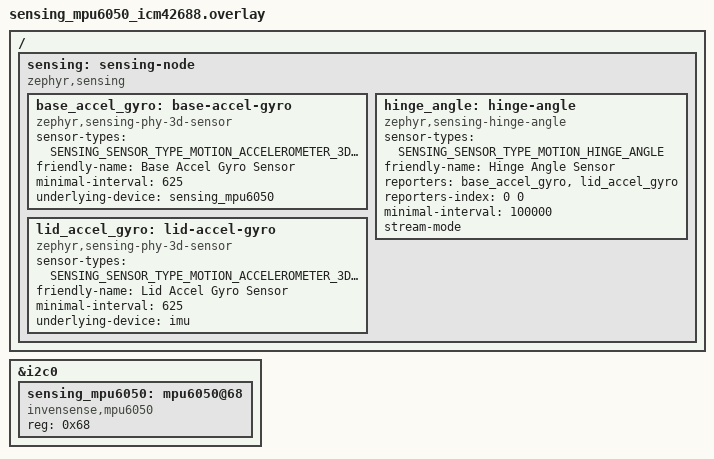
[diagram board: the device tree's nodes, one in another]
/* SPDX-License-Identifier: Apache-2.0 OR MIT */
/*
 * samples/subsys/sensing/simple's sensing node, as its native_sim overlay
 * builds it (one sensor on I2C, one on SPI), on parts the harness has: the
 * base an MPU-6050 at 0x68 on I2C0 (i2c0.overlay), the lid the rig's
 * ICM-42688 on SPI0 (devices/icm4268x/test/dut/rp2.overlay, label imu),
 * and the hinge angle between them. The harness serves one I2C target per
 * bus, so the two cannot share I2C0.
 */
#include <zephyr/sensing/sensing_sensor_types.h>

&i2c0 {
	sensing_mpu6050: mpu6050@68 {
		compatible = "invensense,mpu6050";
		reg = <0x68>;
		status = "okay";
	};
};

/ {
	sensing: sensing-node {
		compatible = "zephyr,sensing";
		status = "okay";

		base_accel_gyro: base-accel-gyro {
			compatible = "zephyr,sensing-phy-3d-sensor";
			status = "okay";
			sensor-types = <SENSING_SENSOR_TYPE_MOTION_ACCELEROMETER_3D
					SENSING_SENSOR_TYPE_MOTION_GYROMETER_3D>;
			friendly-name = "Base Accel Gyro Sensor";
			minimal-interval = <625>;
			underlying-device = <&sensing_mpu6050>;
		};

		lid_accel_gyro: lid-accel-gyro {
			compatible = "zephyr,sensing-phy-3d-sensor";
			status = "okay";
			sensor-types = <SENSING_SENSOR_TYPE_MOTION_ACCELEROMETER_3D
					SENSING_SENSOR_TYPE_MOTION_GYROMETER_3D>;
			friendly-name = "Lid Accel Gyro Sensor";
			minimal-interval = <625>;
			underlying-device = <&imu>;
		};

		hinge_angle: hinge-angle {
			compatible = "zephyr,sensing-hinge-angle";
			status = "okay";
			sensor-types = <SENSING_SENSOR_TYPE_MOTION_HINGE_ANGLE>;
			friendly-name = "Hinge Angle Sensor";
			reporters = <&base_accel_gyro &lid_accel_gyro>;
			reporters-index = <0 0>;
			minimal-interval = <100000>;
			stream-mode;
		};
	};
};
